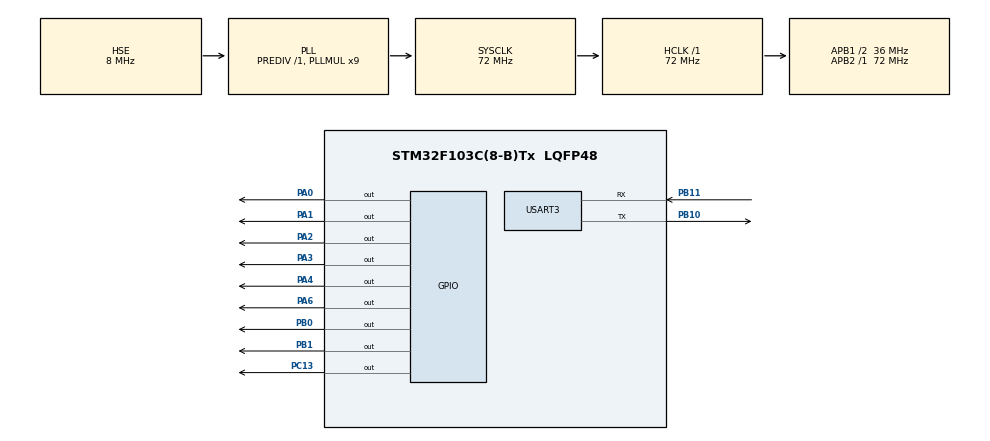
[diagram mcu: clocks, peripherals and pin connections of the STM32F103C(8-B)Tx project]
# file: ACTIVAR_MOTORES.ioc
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Mcu.Family=STM32F1
Mcu.Name=STM32F103C(8-B)Tx
Mcu.Package=LQFP48
NVIC.PriorityGroup=NVIC_PRIORITYGROUP_4
PA0-WKUP.Signal=GPIO_Output
PA1.Signal=GPIO_Output
PA13.Mode=Serial_Wire
PA13.Signal=SYS_JTMS-SWDIO
PA14.Mode=Serial_Wire
PA14.Signal=SYS_JTCK-SWCLK
PA2.Signal=GPIO_Output
PA3.Signal=GPIO_Output
PA4.Signal=GPIO_Output
PA6.Signal=GPIO_Output
PB0.Signal=GPIO_Output
PB1.Signal=GPIO_Output
PB10.Mode=Asynchronous
PB10.Signal=USART3_TX
PB11.Mode=Asynchronous
PB11.Signal=USART3_RX
PC13-TAMPER-RTC.Signal=GPIO_Output
PD0-OSC_IN.Mode=HSE-External-Oscillator
PD0-OSC_IN.Signal=RCC_OSC_IN
PD1-OSC_OUT.Mode=HSE-External-Oscillator
PD1-OSC_OUT.Signal=RCC_OSC_OUT
ProjectManager.HeapSize=0x200
ProjectManager.StackSize=0x400
ProjectManager.TargetToolchain=STM32CubeIDE
RCC.AHBFreq_Value=72000000
RCC.APB1CLKDivider=RCC_HCLK_DIV2
RCC.APB1Freq_Value=36000000
RCC.APB1TimFreq_Value=72000000
RCC.APB2Freq_Value=72000000
RCC.APB2TimFreq_Value=72000000
RCC.HCLKFreq_Value=72000000
RCC.PLLMUL=RCC_PLL_MUL9
RCC.PLLSourceVirtual=RCC_PLLSOURCE_HSE
RCC.SYSCLKFreq_VALUE=72000000
RCC.SYSCLKSource=RCC_SYSCLKSOURCE_PLLCLK
RCC.USBFreq_Value=72000000
USART3.VirtualMode=VM_ASYNC
board=custom

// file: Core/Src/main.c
/* USER CODE BEGIN Header */
/**
  ******************************************************************************
  * @file           : main.c
  * @brief          : Carro Bluetooth - USART3 con PULL-UP (Final)
  ******************************************************************************
  */
/* USER CODE END Header */

#include "main.h"

UART_HandleTypeDef huart3;
uint8_t rx_data;
volatile char comando_actual = 'S';

void SystemClock_Config(void);
static void MX_GPIO_Init(void);
static void MX_USART3_UART_Init(void);

int main(void)
{
  HAL_Init();
  SystemClock_Config();
  MX_GPIO_Init();
  MX_USART3_UART_Init();

  /* USER CODE BEGIN 2 */
  // 1. ACTIVAR PULL-UP EN EL PIN PB11 (RX) PARA EVITAR RUIDO
  GPIO_InitTypeDef GPIO_InitStruct = {0};
  __HAL_RCC_GPIOB_CLK_ENABLE();
  GPIO_InitStruct.Pin = GPIO_PIN_11;
  GPIO_InitStruct.Mode = GPIO_MODE_INPUT;
  GPIO_InitStruct.Pull = GPIO_PULLUP;
  HAL_GPIO_Init(GPIOB, &GPIO_InitStruct);

  // 2. Habilitar la recepción por interrupción (Bluetooth)
  HAL_UART_Receive_IT(&huart3, &rx_data, 1);
  /* USER CODE END 2 */

  while (1)
  {
    // Comando Adelante ('F')
    if (comando_actual == 'F') {
        HAL_GPIO_WritePin(GPIOA, GPIO_PIN_1, GPIO_PIN_SET);
        HAL_GPIO_WritePin(GPIOA, GPIO_PIN_2, GPIO_PIN_RESET);
        HAL_GPIO_WritePin(GPIOA, GPIO_PIN_0, GPIO_PIN_SET); // ENA al 100%

        HAL_GPIO_WritePin(GPIOB, GPIO_PIN_0, GPIO_PIN_SET);
        HAL_GPIO_WritePin(GPIOB, GPIO_PIN_1, GPIO_PIN_RESET);
        HAL_GPIO_WritePin(GPIOA, GPIO_PIN_6, GPIO_PIN_SET); // ENB al 100%
    }
    // Comando Atrás ('B')
    else if (comando_actual == 'B') {
        HAL_GPIO_WritePin(GPIOA, GPIO_PIN_1, GPIO_PIN_RESET);
        HAL_GPIO_WritePin(GPIOA, GPIO_PIN_2, GPIO_PIN_SET);
        HAL_GPIO_WritePin(GPIOA, GPIO_PIN_0, GPIO_PIN_SET);

        HAL_GPIO_WritePin(GPIOB, GPIO_PIN_0, GPIO_PIN_RESET);
        HAL_GPIO_WritePin(GPIOB, GPIO_PIN_1, GPIO_PIN_SET);
        HAL_GPIO_WritePin(GPIOA, GPIO_PIN_6, GPIO_PIN_SET);
    }
    // Comando Izquierda ('L')
    else if (comando_actual == 'L') {
        HAL_GPIO_WritePin(GPIOA, GPIO_PIN_1, GPIO_PIN_RESET);
        HAL_GPIO_WritePin(GPIOA, GPIO_PIN_2, GPIO_PIN_RESET);
        HAL_GPIO_WritePin(GPIOA, GPIO_PIN_0, GPIO_PIN_RESET); // Apaga ENA

        HAL_GPIO_WritePin(GPIOB, GPIO_PIN_0, GPIO_PIN_SET);
        HAL_GPIO_WritePin(GPIOB, GPIO_PIN_1, GPIO_PIN_RESET);
        HAL_GPIO_WritePin(GPIOA, GPIO_PIN_6, GPIO_PIN_SET);
    }
    // Comando Derecha ('R')
    else if (comando_actual == 'R') {
        HAL_GPIO_WritePin(GPIOA, GPIO_PIN_1, GPIO_PIN_SET);
        HAL_GPIO_WritePin(GPIOA, GPIO_PIN_2, GPIO_PIN_RESET);
        HAL_GPIO_WritePin(GPIOA, GPIO_PIN_0, GPIO_PIN_SET);

        HAL_GPIO_WritePin(GPIOB, GPIO_PIN_0, GPIO_PIN_RESET);
        HAL_GPIO_WritePin(GPIOB, GPIO_PIN_1, GPIO_PIN_RESET);
        HAL_GPIO_WritePin(GPIOA, GPIO_PIN_6, GPIO_PIN_RESET); // Apaga ENB
    }
    // Detener ('S')
    else {
        HAL_GPIO_WritePin(GPIOA, GPIO_PIN_1, GPIO_PIN_RESET);
        HAL_GPIO_WritePin(GPIOA, GPIO_PIN_2, GPIO_PIN_RESET);
        HAL_GPIO_WritePin(GPIOA, GPIO_PIN_0, GPIO_PIN_RESET);
        HAL_GPIO_WritePin(GPIOB, GPIO_PIN_0, GPIO_PIN_RESET);
        HAL_GPIO_WritePin(GPIOB, GPIO_PIN_1, GPIO_PIN_RESET);
        HAL_GPIO_WritePin(GPIOA, GPIO_PIN_6, GPIO_PIN_RESET);
    }
  }
}

void SystemClock_Config(void)
{
  RCC_OscInitTypeDef RCC_OscInitStruct = {0};
  RCC_ClkInitTypeDef RCC_ClkInitStruct = {0};

  RCC_OscInitStruct.OscillatorType = RCC_OSCILLATORTYPE_HSE;
  RCC_OscInitStruct.HSEState = RCC_HSE_ON;
  RCC_OscInitStruct.HSEPredivValue = RCC_HSE_PREDIV_DIV1;
  RCC_OscInitStruct.HSIState = RCC_HSI_ON;
  RCC_OscInitStruct.PLL.PLLState = RCC_PLL_ON;
  RCC_OscInitStruct.PLL.PLLSource = RCC_PLLSOURCE_HSE;
  RCC_OscInitStruct.PLL.PLLMUL = RCC_PLL_MUL9;
  if (HAL_RCC_OscConfig(&RCC_OscInitStruct) != HAL_OK) Error_Handler();

  RCC_ClkInitStruct.ClockType = RCC_CLOCKTYPE_HCLK|RCC_CLOCKTYPE_SYSCLK
                              |RCC_CLOCKTYPE_PCLK1|RCC_CLOCKTYPE_PCLK2;
  RCC_ClkInitStruct.SYSCLKSource = RCC_SYSCLKSOURCE_PLLCLK;
  RCC_ClkInitStruct.AHBCLKDivider = RCC_SYSCLK_DIV1;
  RCC_ClkInitStruct.APB1CLKDivider = RCC_HCLK_DIV2;
  RCC_ClkInitStruct.APB2CLKDivider = RCC_HCLK_DIV1;

  if (HAL_RCC_ClockConfig(&RCC_ClkInitStruct, FLASH_LATENCY_2) != HAL_OK) Error_Handler();
}

static void MX_USART3_UART_Init(void)
{
  huart3.Instance = USART3;
  huart3.Init.BaudRate = 115200;
  huart3.Init.WordLength = UART_WORDLENGTH_8B;
  huart3.Init.StopBits = UART_STOPBITS_1;
  huart3.Init.Parity = UART_PARITY_NONE;
  huart3.Init.Mode = UART_MODE_TX_RX;
  huart3.Init.HwFlowCtl = UART_HWCONTROL_NONE;
  huart3.Init.OverSampling = UART_OVERSAMPLING_16;
  if (HAL_UART_Init(&huart3) != HAL_OK) Error_Handler();
}

static void MX_GPIO_Init(void)
{
  GPIO_InitTypeDef GPIO_InitStruct = {0};

  __HAL_RCC_GPIOA_CLK_ENABLE();
  __HAL_RCC_GPIOB_CLK_ENABLE();

  // Poner pines de motor en bajo al inicio
  HAL_GPIO_WritePin(GPIOA, GPIO_PIN_0|GPIO_PIN_1|GPIO_PIN_2|GPIO_PIN_6, GPIO_PIN_RESET);
  HAL_GPIO_WritePin(GPIOB, GPIO_PIN_0|GPIO_PIN_1, GPIO_PIN_RESET);

  // Configurar PA0, PA1, PA2, PA6 como salidas (Motores)
  GPIO_InitStruct.Pin = GPIO_PIN_0|GPIO_PIN_1|GPIO_PIN_2|GPIO_PIN_6;
  GPIO_InitStruct.Mode = GPIO_MODE_OUTPUT_PP;
  GPIO_InitStruct.Pull = GPIO_NOPULL;
  GPIO_InitStruct.Speed = GPIO_SPEED_FREQ_LOW;
  HAL_GPIO_Init(GPIOA, &GPIO_InitStruct);

  // Configurar PB0, PB1 como salidas (Motores)
  GPIO_InitStruct.Pin = GPIO_PIN_0|GPIO_PIN_1;
  GPIO_InitStruct.Mode = GPIO_MODE_OUTPUT_PP;
  GPIO_InitStruct.Pull = GPIO_NOPULL;
  GPIO_InitStruct.Speed = GPIO_SPEED_FREQ_LOW;
  HAL_GPIO_Init(GPIOB, &GPIO_InitStruct);
}

/* USER CODE BEGIN 4 */
void HAL_UART_RxCpltCallback(UART_HandleTypeDef *huart)
{
    if (huart->Instance == USART3)
    {
        // Solo guardar comandos válidos, ignorando cualquier ruido
        if (rx_data == 'F' || rx_data == 'B' || rx_data == 'L' || rx_data == 'R' || rx_data == 'S') {
            comando_actual = rx_data;
        }

        // Volver a habilitar la interrupción
        HAL_UART_Receive_IT(&huart3, &rx_data, 1);
    }
}
/* USER CODE END 4 */

void Error_Handler(void)
{
  __disable_irq();
  while (1)
  {
  }
}
